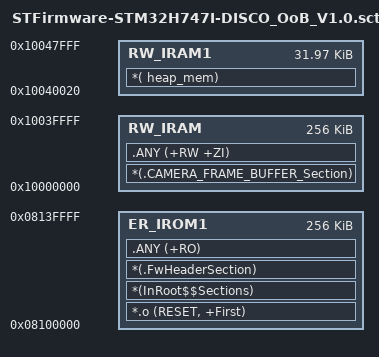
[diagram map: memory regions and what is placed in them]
; *************************************************************
; *** Scatter-Loading Description File generated by uVision ***
; *************************************************************

LR_IROM1 0x08100000 0x00040000  {    ; load region size_region
  ER_IROM1 0x08100000 0x00040000  {  ; load address = execution address
   *.o (RESET, +First)
   *(InRoot$$Sections)
   *(.FwHeaderSection)
   .ANY (+RO)
  }
  RW_IRAM 0x10000000 0x00040000  {  ; RW data
     *(.CAMERA_FRAME_BUFFER_Section)
       .ANY (+RW +ZI)
  }
  RW_IRAM1 0x10040020 0x7FE0  {  ; RW data
       *( heap_mem)
}
}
